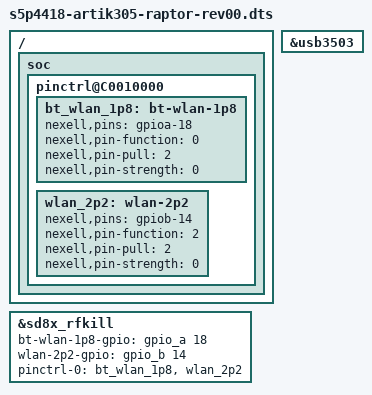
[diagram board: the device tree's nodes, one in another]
/*
 * Copyright (C) 2017 Samsung Electronics.
 * Author: Jaewon Kim <jaewon02.kim@samsung.co.kr>
 *
 * This program is free software; you can redistribute it and/or
 * modify it under the terms of the GNU General Public License
 * as published by the Free Software Foundation; either version 2
 * of the License, or (at your option) any later version.
 *
 * This program is distributed in the hope that it will be useful,
 * but WITHOUT ANY WARRANTY; without even the implied warranty of
 * MERCHANTABILITY or FITNESS FOR A PARTICULAR PURPOSE.  See the
 * GNU General Public License for more details.
 *
 * You should have received a copy of the GNU General Public License
 * along with this program.  If not, see <http://www.gnu.org/licenses/>.
 */

/dts-v1/;
#include "s5p4418-artik305-raptor-common.dtsi"
/ {
	soc {
		pinctrl@C0010000 {
			bt_wlan_1p8: bt-wlan-1p8 {
				nexell,pins = "gpioa-18";
				nexell,pin-function = <0>;
				nexell,pin-pull = <2>;
				nexell,pin-strength = <0>;
			};
			wlan_2p2: wlan-2p2 {
				nexell,pins = "gpiob-14";
				nexell,pin-function = <2>;
				nexell,pin-pull = <2>;
				nexell,pin-strength = <0>;
			};
		};
	};
};

&sd8x_rfkill {
	bt-wlan-1p8-gpio = <&gpio_a 18 0>; /* GPIOA18=BT_WLAN_1P8_PDN output*/
	wlan-2p2-gpio = <&gpio_b 14 0>; /* GPIOB14=WLAN_2P2_PDN output*/
	pinctrl-names = "default";
	pinctrl-0 = <&bt_wlan_1p8 &wlan_2p2>;
};

&usb3503 {
	/delete-property/connect-gpios;
};
